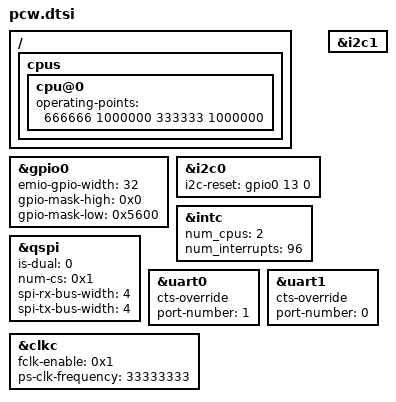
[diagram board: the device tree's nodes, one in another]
/*
 * CAUTION: This file is automatically generated by Xilinx.
 * Version: XSCT 
 * Today is: Wed Feb 12 16:05:35 2025
 */


/ {
	cpus {
		cpu@0 {
			operating-points = <666666 1000000 333333 1000000>;
		};
	};
};

&gpio0 {
	emio-gpio-width = <32>;
	gpio-mask-high = <0x0>;
	gpio-mask-low = <0x5600>;
};
&i2c0 {
	i2c-reset = <&gpio0 13 0>;
	status = "okay";
};
&i2c1 {
	status = "okay";
};
&intc {
	num_cpus = <2>;
	num_interrupts = <96>;
};
&qspi {
	is-dual = <0>;
	num-cs = <0x1>;
	spi-rx-bus-width = <4>;
	spi-tx-bus-width = <4>;
	status = "okay";
};
&uart0 {
	cts-override ;
	device_type = "serial";
	port-number = <1>;
	status = "okay";
};
&uart1 {
	cts-override ;
	device_type = "serial";
	port-number = <0>;
	status = "okay";
};
&clkc {
	fclk-enable = <0x1>;
	ps-clk-frequency = <33333333>;
};
